# MU3E_CHARGE_INJECTION_PULSER register map
Vendor: Mu3e; Series: MU3E_FPGA_IP; File version: 4.0.5
CMSIS-SVD description of the charge injection pulser control aperture. BaseAddress is 0 because this file describes the relative CSR aperture of the IP; system integration supplies the live slave base address.
Registers are 32-bit, write-only, reset 0x0 unless marked. A register's access mark holds for its fields unless they carry their own. Offsets are from the block's base; lines under a group give offsets from that group; [hi:lo] are bit positions; {n}, {i} and the like mark numbered series; 'fields as' and 'values as' point back to an identical list; <NAME> marks a mode.

## Memory map
0x00000000 CHARGE_INJECTION_PULSER_CSR size 0x4 — Single-word write-only CSR aperture for charge-injection pulse generation.

## CHARGE_INJECTION_PULSER_CSR — Single-word write-only CSR aperture for charge-injection pulse generation.
Base 0x00000000
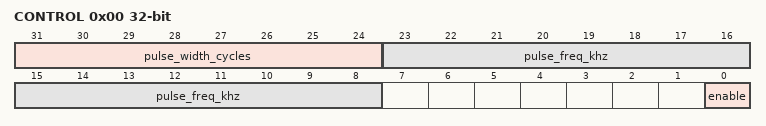
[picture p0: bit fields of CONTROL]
0x00 CONTROL — Write-only charge-injection pulser control word. Bit 0 enables the generator. Bits [23:8] program the pulse repetition frequency in kHz. Bits [31:24] program the pulse width in clock cycles. Reads are not implemented by the RTL and should not be issued.
  [31:24] pulse_width_cycles — Pulse width in clock cycles. Zero selects the compile-time default.
  [23:8] pulse_freq_khz — Pulse repetition frequency in kHz. Zero selects the compile-time default.
  [0] enable — 1 enables periodic pulse generation; 0 disables the output.
